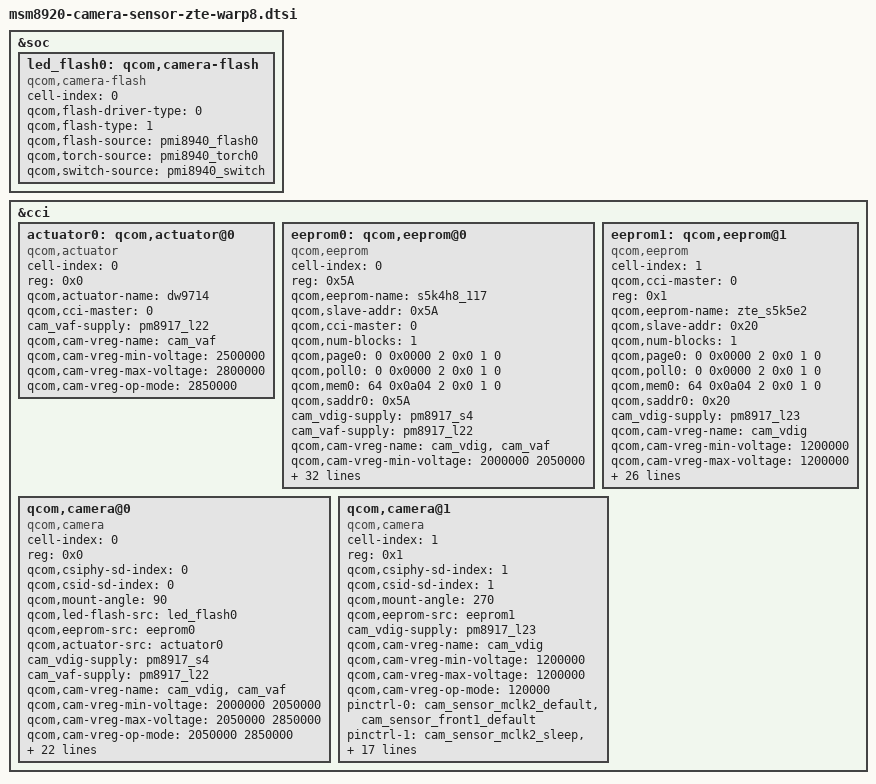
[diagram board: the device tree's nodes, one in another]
/*
 * Copyright (c) 2015-2016, The Linux Foundation. All rights reserved.
 *
 * This program is free software; you can redistribute it and/or modify
 * it under the terms of the GNU General Public License version 2 and
 * only version 2 as published by the Free Software Foundation.
 *
 * This program is distributed in the hope that it will be useful,
 * but WITHOUT ANY WARRANTY; without even the implied warranty of
 * MERCHANTABILITY or FITNESS FOR A PARTICULAR PURPOSE.  See the
 * GNU General Public License for more details.
 */

&soc {
	led_flash0: qcom,camera-flash {
		cell-index = <0>;
		compatible = "qcom,camera-flash";
		qcom,flash-driver-type = <0>;
		qcom,flash-type = <1>;
		//qcom,flash-source = <&pmi8940_flash0 &pmi8940_flash1>;
		//qcom,torch-source = <&pmi8940_torch0 &pmi8940_torch1>;
		qcom,flash-source = <&pmi8940_flash0 >;
		qcom,torch-source = <&pmi8940_torch0 >;
		qcom,switch-source = <&pmi8940_switch>;
	};
};

&cci {
	actuator0: qcom,actuator@0 {
		cell-index = <0>;
		reg = <0x0>;
		compatible = "qcom,actuator";
		qcom,actuator-name = "dw9714";
		qcom,cci-master = <0>;
		cam_vaf-supply = <&pm8917_l22>;
		qcom,cam-vreg-name = "cam_vaf";
		qcom,cam-vreg-min-voltage = <2500000>;
		qcom,cam-vreg-max-voltage = <2800000>;
		qcom,cam-vreg-op-mode = <2850000>;
	};

	eeprom0: qcom,eeprom@0 {
		cell-index = <0>;
		reg = <0x5A>;
		qcom,eeprom-name = "s5k4h8_117";
		compatible = "qcom,eeprom";
		qcom,slave-addr = <0x5A>;
		qcom,cci-master = <0>;
		qcom,num-blocks = <1>;
		qcom,page0 = <0 0x0000 2 0x0 1 0>;
		qcom,poll0 = <0 0x0000 2 0x0 1 0>;
		qcom,mem0  = <64 0x0a04 2 0x0 1 0>;
/*
		qcom,num-blocks = <5>;
		qcom,page0 = <0 0x0000 2 0x0 1 0>;
		qcom,poll0 = <0 0x0000 2 0x0 1 0>;
		qcom,mem0	= <20 0x0A04 2 0x0 1 0>; //page15 awb&mid group1
		qcom,page1 = <0 0x0000 2 0x0 1 0>;
		qcom,poll1 = <0 0x0000 2 0x0 1 0>;
		qcom,mem1	= <20 0x0A1A 2 0x0 1 0>; //page15 awb&mid group1
		qcom,page2 = <0 0x0000 2 0x0 1 0>;
		qcom,poll2 = <0 0x0000 2 0x0 1 0>;
		qcom,mem2	= <4 0x0A31 2 0x0 1 0>; //page15 af group1
		qcom,page3 = <0 0x0000 2 0x0 1 0>;
		qcom,poll3 = <0 0x0000 2 0x0 1 0>;
		qcom,mem3	= <4 0x0A38 2 0x0 1 0>; //page15 af group2
		qcom,page4 = <0 0x0000 2 0x0 1 0>;
		qcom,poll4 = <0 0x0000 2 0x0 1 0>;
		qcom,mem4	= <1 0x0A1B 2 0x0 1 0>; //page 9 lsc group2
*/
		qcom,saddr0 = <0x5A>;
		cam_vdig-supply = <&pm8917_s4>;
		cam_vaf-supply = <&pm8917_l22>;
		qcom,cam-vreg-name ="cam_vdig","cam_vaf";
		qcom,cam-vreg-min-voltage = <2000000 2050000>;
		qcom,cam-vreg-max-voltage = <2050000 2850000>;
		qcom,cam-vreg-op-mode = <2050000 2850000>;
		pinctrl-names = "cam_default", "cam_suspend";
		pinctrl-0 = <&cam_sensor_mclk0_default
			&cam_sensor_rear_default>;
		pinctrl-1 = <&cam_sensor_mclk0_sleep
			&cam_sensor_rear_sleep>;
		gpios = <&tlmm 26 0>,
			<&tlmm 36 0>,
			<&tlmm 35 0>,
			<&tlmm 129 0>,
			<&tlmm 68 0>,
			<&tlmm 62 0>;
		qcom,gpio-reset = <1>;
		qcom,gpio-standby = <2>;
		qcom,gpio-vana = <3>;
		qcom,gpio-vio = <4>;
		qcom,gpio-vdig = <5>;
		qcom,gpio-req-tbl-num = <0 1 2 3 4 5>;
		qcom,gpio-req-tbl-flags = <1 0 0 0 0 0>;
		qcom,gpio-req-tbl-label = "CAMIF_MCLK0",
			"CAM_RESET0",
			"CAM_STANDBY0",
			"CAM_VANA",
			"CAM_VIO",
			"CAM_VDIG";
		qcom,cam-power-seq-type = "sensor_gpio", "sensor_gpio", "sensor_gpio",
		"sensor_vreg","sensor_gpio","sensor_clk", "sensor_gpio","sensor_gpio";
		qcom,cam-power-seq-val ="sensor_gpio_reset","sensor_gpio_standby","sensor_gpio_vana",
		"cam_vdig", "sensor_gpio_vio","sensor_cam_mclk",  "sensor_gpio_reset","sensor_gpio_standby";
		qcom,cam-power-seq-cfg-val = <0 1 1 1 1 24000000 1 0>;
		qcom,cam-power-seq-delay = <1 1  0 0 0 1 1 10>;
		status = "ok";
		clocks = <&clock_gcc clk_mclk0_clk_src>,
			<&clock_gcc clk_gcc_camss_mclk0_clk>;
		clock-names = "cam_src_clk", "cam_clk";
		qcom,clock-rates = <24000000 0>;
	};

	eeprom1: qcom,eeprom@1 {
		cell-index = <1>;
		compatible = "qcom,eeprom";
		qcom,cci-master = <0>;
		reg = <0x1>;
		qcom,eeprom-name = "zte_s5k5e2";
		qcom,slave-addr = <0x20>;
		qcom,num-blocks = <1>;
		qcom,page0 = <0 0x0000 2 0x0 1 0>;
		qcom,poll0 = <0 0x0000 2 0x0 1 0>;
		qcom,mem0  = <64 0x0a04 2 0x0 1 0>;
		/*
		qcom,page1 = <0 0x0000 2 0x0 1 0>;
		qcom,poll1 = <0 0x0000 2 0x0 1 0>;
		qcom,mem1  = <64 0x0a04 2 0x0 1 0>;
		qcom,page2 = <0 0x0000 2 0x0 1 0>;
		qcom,poll2 = <0 0x0000 2 0x0 1 0>;
		qcom,mem2  = <64 0x0a04 2 0x0 1 0>;
		qcom,page3 = <0 0x0000 2 0x0 1 0>;
		qcom,poll3 = <0 0x0000 2 0x0 1 0>;
		qcom,mem3  = <64 0x0a04 2 0x0 1 0>;
		qcom,page4 = <0 0x0000 2 0x0 1 0>;
		qcom,poll4 = <0 0x0000 2 0x0 1 0>;
		qcom,mem4  = <64 0x0a04 2 0x0 1 0>;
		qcom,page5 = <0 0x0000 2 0x0 1 0>;
		qcom,poll5 = <0 0x0000 2 0x0 1 0>;
		qcom,mem5  = <64 0x0a04 2 0x0 1 0>;
		qcom,page6 = <0 0x0000 2 0x0 1 0>;
		qcom,poll6 = <0 0x0000 2 0x0 1 0>;
		qcom,mem6  = <40 0x0a04 2 0x0 1 0>;
		*/
		qcom,saddr0 = <0x20>;
		cam_vdig-supply = <&pm8917_l23>;
		qcom,cam-vreg-name = "cam_vdig";
		qcom,cam-vreg-min-voltage = <1200000>;
		qcom,cam-vreg-max-voltage = <1200000 >;
		qcom,cam-vreg-op-mode = <120000 >;
		pinctrl-names = "cam_default", "cam_suspend";
		pinctrl-0 = <&cam_sensor_mclk2_default
			&cam_sensor_front1_default>;
		pinctrl-1 = <&cam_sensor_mclk2_sleep
			&cam_sensor_front1_sleep>;
		gpios = <&tlmm 28 0>,
			<&tlmm 40 0>,
			<&tlmm 39 0>,
			<&tlmm 96 0>,
			<&tlmm 68 0>;
		qcom,gpio-reset = <1>;
		qcom,gpio-standby = <2>;
		qcom,gpio-vana = <3>;
		qcom,gpio-vio = <4>;
		qcom,gpio-req-tbl-num = <0 1 2 3 4 >;
		qcom,gpio-req-tbl-flags = <1 0 0 0 0>;
		qcom,gpio-req-tbl-label = "CAMIF_MCLK2",
			"CAM_RESET1",
			"CAM_STANDBY1",
			"CAM_VANA",
			"CAM_VIO1";
		qcom,cam-power-seq-type = "sensor_gpio", "sensor_gpio",
			"sensor_vreg", "sensor_gpio", "sensor_gpio","sensor_clk";
		qcom,cam-power-seq-val ="sensor_gpio_reset","sensor_gpio_vana",
			"cam_vdig", "sensor_gpio_vio", "sensor_gpio_reset", "sensor_cam_mclk";
		qcom,cam-power-seq-cfg-val = <0 1 1 1 1 24000000>;
		qcom,cam-power-seq-delay = <5 5 10 1 10 10>;
		status = "ok";
		clocks = <&clock_gcc clk_mclk2_clk_src>,
			<&clock_gcc clk_gcc_camss_mclk2_clk>;
		clock-names = "cam_src_clk", "cam_clk";
		qcom,clock-rates = <24000000 0>;
	};

	qcom,camera@0 {
		cell-index = <0>;
		compatible = "qcom,camera";
		reg = <0x0>;
		qcom,csiphy-sd-index = <0>;
		qcom,csid-sd-index = <0>;
		qcom,mount-angle = <90>;
		qcom,led-flash-src = <&led_flash0>;
		qcom,eeprom-src = <&eeprom0>;
		qcom,actuator-src = <&actuator0>;
		//zte,in_sensor_otp = <1>;
		cam_vdig-supply = <&pm8917_s4>;
		cam_vaf-supply = <&pm8917_l22>;
		qcom,cam-vreg-name ="cam_vdig","cam_vaf";
		qcom,cam-vreg-min-voltage = <2000000 2050000>;
		qcom,cam-vreg-max-voltage = <2050000 2850000>;
		qcom,cam-vreg-op-mode = <2050000 2850000>;
		pinctrl-names = "cam_default", "cam_suspend";
		pinctrl-0 = <&cam_sensor_mclk0_default
			&cam_sensor_rear_default>;
		pinctrl-1 = <&cam_sensor_mclk0_sleep
			&cam_sensor_rear_sleep>;
		gpios = <&tlmm 26 0>,
			<&tlmm 36 0>,
			<&tlmm 35 0>,
			<&tlmm 129 0>,
			<&tlmm 68 0>,
			<&tlmm 62 0>;
		qcom,gpio-reset = <1>;
		qcom,gpio-standby = <2>;
		qcom,gpio-vana = <3>;
		qcom,gpio-vio = <4>;
		qcom,gpio-vdig = <5>;
		qcom,gpio-req-tbl-num = <0 1 2 3 4 5>;
		qcom,gpio-req-tbl-flags = <1 0 0 0 0 0>;
		qcom,gpio-req-tbl-label = "CAMIF_MCLK0",
			"CAM_RESET0",
			"CAM_STANDBY0",
			"CAM_VANA",
			"CAM_VIO",
			"CAM_VDIG";
		qcom,sensor-position = <0>;
		qcom,sensor-mode = <0>;
		qcom,cci-master = <0>;
		status = "ok";
		clocks = <&clock_gcc clk_mclk0_clk_src>,
			<&clock_gcc clk_gcc_camss_mclk0_clk>;
		clock-names = "cam_src_clk", "cam_clk";
		qcom,clock-rates = <24000000 0>;
	};

	qcom,camera@1 {
		cell-index = <1>;
		compatible = "qcom,camera";
		reg = <0x1>;
		qcom,csiphy-sd-index = <1>;
		qcom,csid-sd-index = <1>;
		qcom,mount-angle = <270>;
		qcom,eeprom-src = <&eeprom1>;
		cam_vdig-supply = <&pm8917_l23>;
		qcom,cam-vreg-name = "cam_vdig";
		qcom,cam-vreg-min-voltage = <1200000>;
		qcom,cam-vreg-max-voltage = <1200000 >;
		qcom,cam-vreg-op-mode = <120000 >;
		pinctrl-names = "cam_default","cam_suspend";
		pinctrl-0 = <&cam_sensor_mclk2_default
			&cam_sensor_front1_default>;
		pinctrl-1 = <&cam_sensor_mclk2_sleep
			&cam_sensor_front1_sleep>;

		gpios = <&tlmm 28 0>,
			<&tlmm 40 0>,
			<&tlmm 39 0>,
			<&tlmm 96 0>,
			<&tlmm 68 0>;
		qcom,gpio-reset = <1>;
		qcom,gpio-standby = <2>;
		qcom,gpio-vana = <3>;
		qcom,gpio-vio = <4>;
		qcom,gpio-req-tbl-num = <0 1 2 3 4 >;
		qcom,gpio-req-tbl-flags = <1 0 0 0 0>;
		qcom,gpio-req-tbl-label = "CAMIF_MCLK2",
			"CAM_RESET1",
			"CAM_STANDBY1",
			"CAM_VANA",
			"CAM_VIO1";
		qcom,sensor-position = <1>;
		qcom,sensor-mode = <1>;
		qcom,cci-master = <0>;
		status = "ok";
		clocks = <&clock_gcc clk_mclk2_clk_src>,
			<&clock_gcc clk_gcc_camss_mclk2_clk>;
		clock-names = "cam_src_clk", "cam_clk";
		qcom,clock-rates = <24000000 0>;
	};

};
